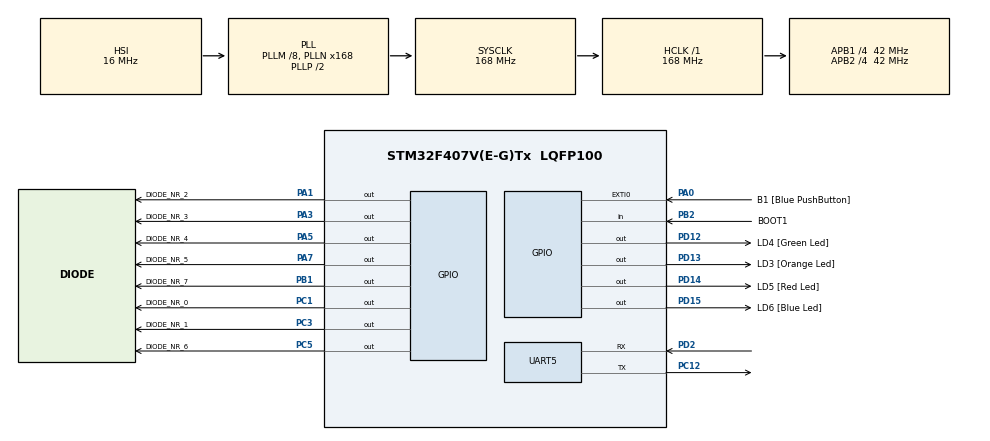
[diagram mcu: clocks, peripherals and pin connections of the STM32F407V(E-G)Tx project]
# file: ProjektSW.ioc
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FREERTOS.Tasks01=defaultTask,0,128,StartDefaultTask,Default,NULL,Dynamic,NULL,NULL
Mcu.Family=STM32F4
Mcu.Name=STM32F407V(E-G)Tx
Mcu.Package=LQFP100
NVIC.PriorityGroup=NVIC_PRIORITYGROUP_4
NVIC.UART5_IRQn=true\:5\:0\:false\:true\:true\:1\:true\:true\:true
PA0-WKUP.GPIO_Label=B1 [Blue PushButton]
PA0-WKUP.Signal=GPXTI0
PA1.GPIO_Label=DIODE_NR_2
PA1.GPIO_ModeDefaultOutputPP=GPIO_MODE_OUTPUT_PP
PA1.GPIO_PuPd=GPIO_NOPULL
PA1.PinState=GPIO_PIN_RESET
PA1.Signal=GPIO_Output
PA13.GPIO_Label=SWDIO
PA13.Mode=Serial_Wire
PA13.Signal=SYS_JTMS-SWDIO
PA14.GPIO_Label=SWCLK
PA14.Mode=Serial_Wire
PA14.Signal=SYS_JTCK-SWCLK
PA3.GPIO_Label=DIODE_NR_3
PA3.GPIO_ModeDefaultOutputPP=GPIO_MODE_OUTPUT_PP
PA3.GPIO_PuPd=GPIO_NOPULL
PA3.PinState=GPIO_PIN_RESET
PA3.Signal=GPIO_Output
PA5.GPIO_Label=DIODE_NR_4
PA5.Signal=GPIO_Output
PA7.GPIO_Label=DIODE_NR_5
PA7.Signal=GPIO_Output
PB1.GPIO_Label=DIODE_NR_7
PB1.Signal=GPIO_Output
PB2.GPIO_Label=BOOT1
PB2.GPIO_Mode=GPIO_MODE_INPUT
PB2.GPIO_PuPd=GPIO_NOPULL
PB2.Signal=GPIO_Input
PC1.GPIO_Label=DIODE_NR_0
PC1.GPIO_ModeDefaultOutputPP=GPIO_MODE_OUTPUT_PP
PC1.GPIO_PuPd=GPIO_NOPULL
PC1.PinState=GPIO_PIN_RESET
PC1.Signal=GPIO_Output
PC12.Mode=Asynchronous
PC12.Signal=UART5_TX
PC3.GPIO_Label=DIODE_NR_1
PC3.GPIO_ModeDefaultOutputPP=GPIO_MODE_OUTPUT_PP
PC3.GPIO_PuPd=GPIO_NOPULL
PC3.PinState=GPIO_PIN_RESET
PC3.Signal=GPIO_Output
PC5.GPIO_Label=DIODE_NR_6
PC5.Signal=GPIO_Output
PD12.GPIO_Label=LD4 [Green Led]
PD12.GPIO_PuPd=GPIO_NOPULL
PD12.GPIO_Speed=GPIO_SPEED_FREQ_LOW
PD12.Signal=GPIO_Output
PD13.GPIO_Label=LD3 [Orange Led]
PD13.GPIO_PuPd=GPIO_NOPULL
PD13.GPIO_Speed=GPIO_SPEED_FREQ_LOW
PD13.Signal=GPIO_Output
PD14.GPIO_Label=LD5 [Red Led]
PD14.GPIO_PuPd=GPIO_NOPULL
PD14.GPIO_Speed=GPIO_SPEED_FREQ_LOW
PD14.Signal=GPIO_Output
PD15.GPIO_Label=LD6 [Blue Led]
PD15.GPIO_PuPd=GPIO_NOPULL
PD15.GPIO_Speed=GPIO_SPEED_FREQ_LOW
PD15.Signal=GPIO_Output
PD2.Mode=Asynchronous
PD2.Signal=UART5_RX
ProjectManager.HeapSize=0x200
ProjectManager.StackSize=0x400
ProjectManager.TargetToolchain=STM32CubeIDE
RCC.48MHZClocksFreq_Value=48000000
RCC.AHBFreq_Value=168000000
RCC.APB1CLKDivider=RCC_HCLK_DIV4
RCC.APB1Freq_Value=42000000
RCC.APB1TimFreq_Value=84000000
RCC.APB2CLKDivider=RCC_HCLK_DIV4
RCC.APB2Freq_Value=42000000
RCC.APB2TimFreq_Value=84000000
RCC.CortexFreq_Value=168000000
RCC.HCLKFreq_Value=168000000
RCC.HSE_VALUE=8000000
RCC.HSI_VALUE=16000000
RCC.LSE_VALUE=32768
RCC.PLLM=8
RCC.PLLN=168
RCC.PLLQ=7
RCC.SYSCLKFreq_VALUE=168000000
RCC.SYSCLKSource=RCC_SYSCLKSOURCE_PLLCLK
RCC.VCOOutputFreq_Value=336000000
UART5.VirtualMode=Asynchronous
VP_FREERTOS_VS_CMSIS_V1.Mode=CMSIS_V1
board=STM32F407G-DISC1

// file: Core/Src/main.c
/* USER CODE BEGIN Header */
/**
  ******************************************************************************
  * @file           : main.c
  * @brief          : Main program body
  ******************************************************************************
  * @attention
  *
  * <h2><center>&copy; Copyright (c) 2021 STMicroelectronics.
  * All rights reserved.</center></h2>
  *
  * This software component is licensed by ST under Ultimate Liberty license
  * SLA0044, the "License"; You may not use this file except in compliance with
  * the License. You may obtain a copy of the License at:
  *                             www.st.com/SLA0044
  *
  ******************************************************************************
  */
/* USER CODE END Header */
#include "main.h"
#include "cmsis_os.h"

/* USER CODE BEGIN Includes */
#include "generalModule.h"
/* USER CODE END Includes */

UART_HandleTypeDef huart5;

osThreadId defaultTaskHandle;

void SystemClock_Config(void);
static void MX_GPIO_Init(void);
static void MX_UART5_Init(void);
void StartDefaultTask(void const * argument);

static void MX_NVIC_Init(void);

int main(void)
{

  /* MCU Configuration--------------------------------------------------------*/

  /* Reset of all peripherals, Initializes the Flash interface and the Systick. */
  HAL_Init();

  /* Configure the system clock */
  SystemClock_Config();

  /* Initialize all configured peripherals */
  MX_GPIO_Init();
  MX_UART5_Init();

  /* Initialize interrupts */
  MX_NVIC_Init();
  /* USER CODE BEGIN 2 */
  generalModuleInit(&peripheralStruct,&huart5);
  /* USER CODE END 2 */

  /* Create the thread(s) */
  /* definition and creation of defaultTask */
  osThreadDef(defaultTask, StartDefaultTask, osPriorityNormal, 0, 128);
  defaultTaskHandle = osThreadCreate(osThread(defaultTask), NULL);

  /* Start scheduler */
  osKernelStart();

  /* We should never get here as control is now taken by the scheduler */
  /* Infinite loop */
  while (1)
  {

  }
}

void SystemClock_Config(void)
{
  RCC_OscInitTypeDef RCC_OscInitStruct = {0};
  RCC_ClkInitTypeDef RCC_ClkInitStruct = {0};

  /** Configure the main internal regulator output voltage
  */
  __HAL_RCC_PWR_CLK_ENABLE();
  __HAL_PWR_VOLTAGESCALING_CONFIG(PWR_REGULATOR_VOLTAGE_SCALE1);
  /** Initializes the RCC Oscillators according to the specified parameters
  * in the RCC_OscInitTypeDef structure.
  */
  RCC_OscInitStruct.OscillatorType = RCC_OSCILLATORTYPE_HSI;
  RCC_OscInitStruct.HSIState = RCC_HSI_ON;
  RCC_OscInitStruct.HSICalibrationValue = RCC_HSICALIBRATION_DEFAULT;
  RCC_OscInitStruct.PLL.PLLState = RCC_PLL_ON;
  RCC_OscInitStruct.PLL.PLLSource = RCC_PLLSOURCE_HSI;
  RCC_OscInitStruct.PLL.PLLM = 8;
  RCC_OscInitStruct.PLL.PLLN = 168;
  RCC_OscInitStruct.PLL.PLLP = RCC_PLLP_DIV2;
  RCC_OscInitStruct.PLL.PLLQ = 7;
  if (HAL_RCC_OscConfig(&RCC_OscInitStruct) != HAL_OK)
  {
    Error_Handler();
  }
  /** Initializes the CPU, AHB and APB buses clocks
  */
  RCC_ClkInitStruct.ClockType = RCC_CLOCKTYPE_HCLK|RCC_CLOCKTYPE_SYSCLK
                              |RCC_CLOCKTYPE_PCLK1|RCC_CLOCKTYPE_PCLK2;
  RCC_ClkInitStruct.SYSCLKSource = RCC_SYSCLKSOURCE_PLLCLK;
  RCC_ClkInitStruct.AHBCLKDivider = RCC_SYSCLK_DIV1;
  RCC_ClkInitStruct.APB1CLKDivider = RCC_HCLK_DIV4;
  RCC_ClkInitStruct.APB2CLKDivider = RCC_HCLK_DIV4;

  if (HAL_RCC_ClockConfig(&RCC_ClkInitStruct, FLASH_LATENCY_5) != HAL_OK)
  {
    Error_Handler();
  }
}

/**
  * @brief NVIC Configuration.
  * @retval None
  */
static void MX_NVIC_Init(void)
{
  /* UART5_IRQn interrupt configuration */
  HAL_NVIC_SetPriority(UART5_IRQn, 5, 0);
  HAL_NVIC_EnableIRQ(UART5_IRQn);
}

static void MX_UART5_Init(void)
{

  huart5.Instance = UART5;
  huart5.Init.BaudRate = 115200;
  huart5.Init.WordLength = UART_WORDLENGTH_8B;
  huart5.Init.StopBits = UART_STOPBITS_1;
  huart5.Init.Parity = UART_PARITY_NONE;
  huart5.Init.Mode = UART_MODE_TX_RX;
  huart5.Init.HwFlowCtl = UART_HWCONTROL_NONE;
  huart5.Init.OverSampling = UART_OVERSAMPLING_16;
  if (HAL_UART_Init(&huart5) != HAL_OK)
  {
    Error_Handler();
  }

}

static void MX_GPIO_Init(void)
{
  GPIO_InitTypeDef GPIO_InitStruct = {0};

  /* GPIO Ports Clock Enable */
  __HAL_RCC_GPIOC_CLK_ENABLE();
  __HAL_RCC_GPIOA_CLK_ENABLE();
  __HAL_RCC_GPIOB_CLK_ENABLE();
  __HAL_RCC_GPIOD_CLK_ENABLE();

  /*Configure GPIO pin Output Level */
  HAL_GPIO_WritePin(GPIOC, DIODE_NR_0_Pin|DIODE_NR_1_Pin|DIODE_NR_6_Pin, GPIO_PIN_RESET);

  /*Configure GPIO pin Output Level */
  HAL_GPIO_WritePin(GPIOA, DIODE_NR_2_Pin|DIODE_NR_3_Pin|DIODE_NR_4_Pin|DIODE_NR_5_Pin, GPIO_PIN_RESET);

  /*Configure GPIO pin Output Level */
  HAL_GPIO_WritePin(DIODE_NR_7_GPIO_Port, DIODE_NR_7_Pin, GPIO_PIN_RESET);

  /*Configure GPIO pin Output Level */
  HAL_GPIO_WritePin(GPIOD, LD4_Pin|LD3_Pin|LD5_Pin|LD6_Pin, GPIO_PIN_RESET);

  /*Configure GPIO pins : DIODE_NR_0_Pin DIODE_NR_1_Pin DIODE_NR_6_Pin */
  GPIO_InitStruct.Pin = DIODE_NR_0_Pin|DIODE_NR_1_Pin|DIODE_NR_6_Pin;
  GPIO_InitStruct.Mode = GPIO_MODE_OUTPUT_PP;
  GPIO_InitStruct.Pull = GPIO_NOPULL;
  GPIO_InitStruct.Speed = GPIO_SPEED_FREQ_LOW;
  HAL_GPIO_Init(GPIOC, &GPIO_InitStruct);

  /*Configure GPIO pin : B1_Pin */
  GPIO_InitStruct.Pin = B1_Pin;
  GPIO_InitStruct.Mode = GPIO_MODE_IT_RISING;
  GPIO_InitStruct.Pull = GPIO_NOPULL;
  HAL_GPIO_Init(B1_GPIO_Port, &GPIO_InitStruct);

  /*Configure GPIO pins : DIODE_NR_2_Pin DIODE_NR_3_Pin DIODE_NR_4_Pin DIODE_NR_5_Pin */
  GPIO_InitStruct.Pin = DIODE_NR_2_Pin|DIODE_NR_3_Pin|DIODE_NR_4_Pin|DIODE_NR_5_Pin;
  GPIO_InitStruct.Mode = GPIO_MODE_OUTPUT_PP;
  GPIO_InitStruct.Pull = GPIO_NOPULL;
  GPIO_InitStruct.Speed = GPIO_SPEED_FREQ_LOW;
  HAL_GPIO_Init(GPIOA, &GPIO_InitStruct);

  /*Configure GPIO pin : DIODE_NR_7_Pin */
  GPIO_InitStruct.Pin = DIODE_NR_7_Pin;
  GPIO_InitStruct.Mode = GPIO_MODE_OUTPUT_PP;
  GPIO_InitStruct.Pull = GPIO_NOPULL;
  GPIO_InitStruct.Speed = GPIO_SPEED_FREQ_LOW;
  HAL_GPIO_Init(DIODE_NR_7_GPIO_Port, &GPIO_InitStruct);

  /*Configure GPIO pin : BOOT1_Pin */
  GPIO_InitStruct.Pin = BOOT1_Pin;
  GPIO_InitStruct.Mode = GPIO_MODE_INPUT;
  GPIO_InitStruct.Pull = GPIO_NOPULL;
  HAL_GPIO_Init(BOOT1_GPIO_Port, &GPIO_InitStruct);

  /*Configure GPIO pins : LD4_Pin LD3_Pin LD5_Pin LD6_Pin */
  GPIO_InitStruct.Pin = LD4_Pin|LD3_Pin|LD5_Pin|LD6_Pin;
  GPIO_InitStruct.Mode = GPIO_MODE_OUTPUT_PP;
  GPIO_InitStruct.Pull = GPIO_NOPULL;
  GPIO_InitStruct.Speed = GPIO_SPEED_FREQ_LOW;
  HAL_GPIO_Init(GPIOD, &GPIO_InitStruct);

}

/* USER CODE BEGIN 4 */
void HAL_UART_RxCpltCallback(UART_HandleTypeDef *UartHandle){
	if(UartHandle==&huart5){
		generalModuleUartRxInterrupt(&peripheralStruct);
	}
}
/* USER CODE END 4 */

void StartDefaultTask(void const * argument)
{
  for(;;)
  {
    osDelay(1);
  }
}

void Error_Handler(void)
{
  __disable_irq();
  while (1)
  {
  }
}

/************************ (C) COPYRIGHT STMicroelectronics *****END OF FILE****/
